VERSION ""

NS_ :

BS_:

BU_: ENGINE ABS AIRBAG BODY_CONTROL DIAG_TOOL

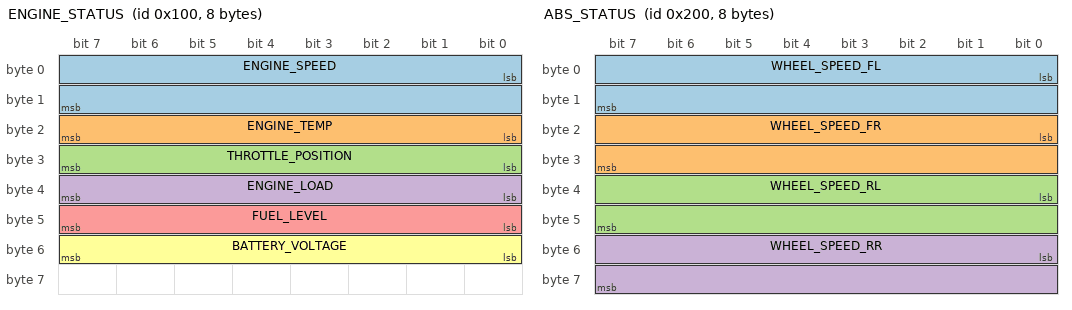
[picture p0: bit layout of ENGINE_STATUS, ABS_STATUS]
BO_ 256 ENGINE_STATUS: 8 ENGINE
 SG_ ENGINE_SPEED : 0|16@1+ (1,0) [0|16383] "rpm" BODY_CONTROL,DIAG_TOOL
 SG_ ENGINE_TEMP : 16|8@1+ (0.5,-40) [-40|127.5] "degC" BODY_CONTROL,DIAG_TOOL
 SG_ THROTTLE_POSITION : 24|8@1+ (0.4,0) [0|100] "%" BODY_CONTROL,DIAG_TOOL
 SG_ ENGINE_LOAD : 32|8@1+ (0.4,0) [0|100] "%" BODY_CONTROL,DIAG_TOOL
 SG_ FUEL_LEVEL : 40|8@1+ (0.4,0) [0|100] "%" BODY_CONTROL,DIAG_TOOL
 SG_ BATTERY_VOLTAGE : 48|8@1+ (0.1,0) [0|25.5] "V" BODY_CONTROL,DIAG_TOOL

BO_ 512 ABS_STATUS: 8 ABS
 SG_ WHEEL_SPEED_FL : 0|16@1+ (0.01,0) [0|300] "kph" BODY_CONTROL,DIAG_TOOL
 SG_ WHEEL_SPEED_FR : 16|16@1+ (0.01,0) [0|300] "kph" BODY_CONTROL,DIAG_TOOL
 SG_ WHEEL_SPEED_RL : 32|16@1+ (0.01,0) [0|300] "kph" BODY_CONTROL,DIAG_TOOL
 SG_ WHEEL_SPEED_RR : 48|16@1+ (0.01,0) [0|300] "kph" BODY_CONTROL,DIAG_TOOL

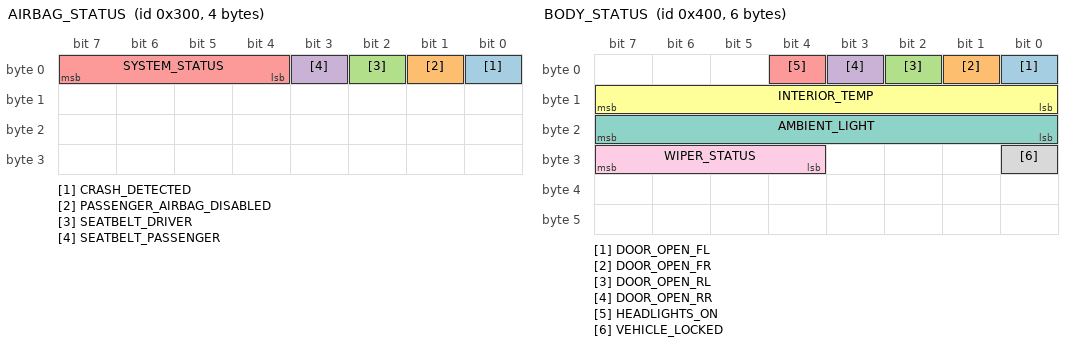
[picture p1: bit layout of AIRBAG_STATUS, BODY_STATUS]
BO_ 768 AIRBAG_STATUS: 4 AIRBAG
 SG_ CRASH_DETECTED : 0|1@1+ (1,0) [0|1] "" BODY_CONTROL,DIAG_TOOL
 SG_ PASSENGER_AIRBAG_DISABLED : 1|1@1+ (1,0) [0|1] "" BODY_CONTROL,DIAG_TOOL
 SG_ SEATBELT_DRIVER : 2|1@1+ (1,0) [0|1] "" BODY_CONTROL,DIAG_TOOL
 SG_ SEATBELT_PASSENGER : 3|1@1+ (1,0) [0|1] "" BODY_CONTROL,DIAG_TOOL
 SG_ SYSTEM_STATUS : 4|4@1+ (1,0) [0|15] "" BODY_CONTROL,DIAG_TOOL

BO_ 1024 BODY_STATUS: 6 BODY_CONTROL
 SG_ DOOR_OPEN_FL : 0|1@1+ (1,0) [0|1] "" DIAG_TOOL
 SG_ DOOR_OPEN_FR : 1|1@1+ (1,0) [0|1] "" DIAG_TOOL
 SG_ DOOR_OPEN_RL : 2|1@1+ (1,0) [0|1] "" DIAG_TOOL
 SG_ DOOR_OPEN_RR : 3|1@1+ (1,0) [0|1] "" DIAG_TOOL
 SG_ HEADLIGHTS_ON : 4|1@1+ (1,0) [0|1] "" DIAG_TOOL
 SG_ INTERIOR_TEMP : 8|8@1+ (0.5,-40) [-40|127.5] "degC" DIAG_TOOL
 SG_ AMBIENT_LIGHT : 16|8@1+ (1,0) [0|255] "lux" DIAG_TOOL
 SG_ VEHICLE_LOCKED : 24|1@1+ (1,0) [0|1] "" DIAG_TOOL
 SG_ WIPER_STATUS : 28|4@1+ (1,0) [0|15] "" DIAG_TOOL

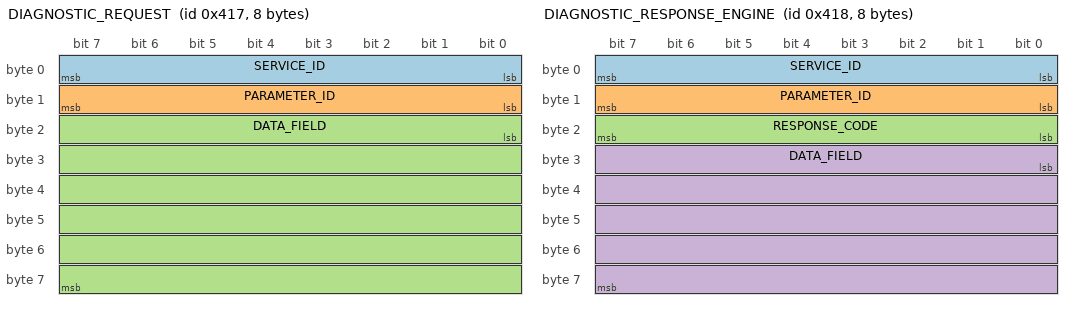
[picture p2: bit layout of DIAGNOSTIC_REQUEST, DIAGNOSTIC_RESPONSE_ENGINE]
BO_ 1047 DIAGNOSTIC_REQUEST: 8 DIAG_TOOL
 SG_ SERVICE_ID : 0|8@1+ (1,0) [0|255] "" ENGINE,ABS,AIRBAG,BODY_CONTROL
 SG_ PARAMETER_ID : 8|8@1+ (1,0) [0|255] "" ENGINE,ABS,AIRBAG,BODY_CONTROL
 SG_ DATA_FIELD : 16|48@1+ (1,0) [0|281474976710655] "" ENGINE,ABS,AIRBAG,BODY_CONTROL

BO_ 1048 DIAGNOSTIC_RESPONSE_ENGINE: 8 ENGINE
 SG_ SERVICE_ID : 0|8@1+ (1,0) [0|255] "" DIAG_TOOL
 SG_ PARAMETER_ID : 8|8@1+ (1,0) [0|255] "" DIAG_TOOL
 SG_ RESPONSE_CODE : 16|8@1+ (1,0) [0|255] "" DIAG_TOOL
 SG_ DATA_FIELD : 24|40@1+ (1,0) [0|1099511627775] "" DIAG_TOOL

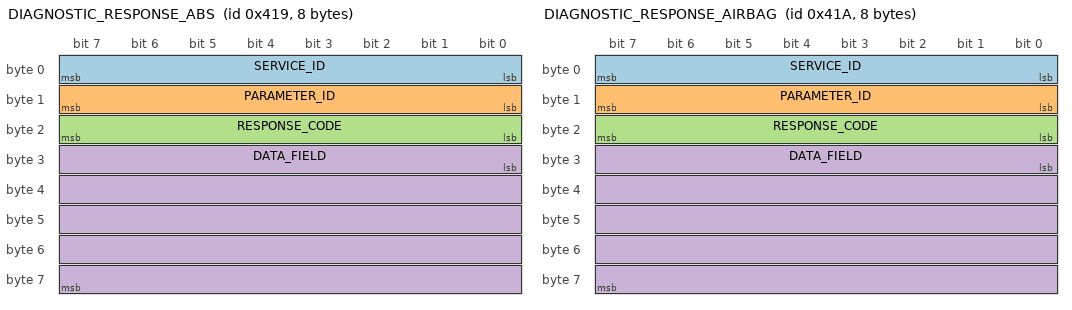
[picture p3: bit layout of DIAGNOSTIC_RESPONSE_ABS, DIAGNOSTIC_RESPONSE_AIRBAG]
BO_ 1049 DIAGNOSTIC_RESPONSE_ABS: 8 ABS
 SG_ SERVICE_ID : 0|8@1+ (1,0) [0|255] "" DIAG_TOOL
 SG_ PARAMETER_ID : 8|8@1+ (1,0) [0|255] "" DIAG_TOOL
 SG_ RESPONSE_CODE : 16|8@1+ (1,0) [0|255] "" DIAG_TOOL
 SG_ DATA_FIELD : 24|40@1+ (1,0) [0|1099511627775] "" DIAG_TOOL

BO_ 1050 DIAGNOSTIC_RESPONSE_AIRBAG: 8 AIRBAG
 SG_ SERVICE_ID : 0|8@1+ (1,0) [0|255] "" DIAG_TOOL
 SG_ PARAMETER_ID : 8|8@1+ (1,0) [0|255] "" DIAG_TOOL
 SG_ RESPONSE_CODE : 16|8@1+ (1,0) [0|255] "" DIAG_TOOL
 SG_ DATA_FIELD : 24|40@1+ (1,0) [0|1099511627775] "" DIAG_TOOL

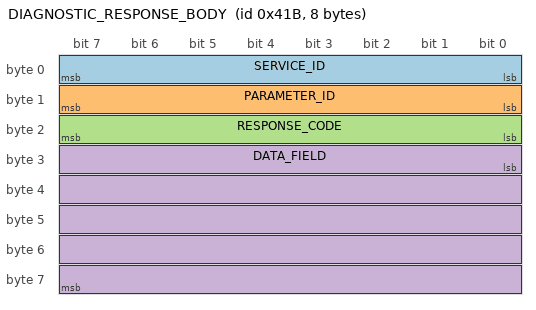
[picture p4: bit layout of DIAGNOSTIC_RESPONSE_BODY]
BO_ 1051 DIAGNOSTIC_RESPONSE_BODY: 8 BODY_CONTROL
 SG_ SERVICE_ID : 0|8@1+ (1,0) [0|255] "" DIAG_TOOL
 SG_ PARAMETER_ID : 8|8@1+ (1,0) [0|255] "" DIAG_TOOL
 SG_ RESPONSE_CODE : 16|8@1+ (1,0) [0|255] "" DIAG_TOOL
 SG_ DATA_FIELD : 24|40@1+ (1,0) [0|1099511627775] "" DIAG_TOOL

BA_DEF_ BO_ "FrameFormat" ENUM "StandardCAN","ExtendedCAN";
BA_ "FrameFormat" BO_ 1048 1;
BA_ "FrameFormat" BO_ 1049 1;
BA_ "FrameFormat" BO_ 1050 1;
BA_ "FrameFormat" BO_ 1051 1;
BA_ "FrameFormat" BO_ 1047 1;

CM_ SG_ 256 ENGINE_SPEED "Current engine RPM";
CM_ SG_ 256 ENGINE_TEMP "Engine coolant temperature";
CM_ SG_ 256 THROTTLE_POSITION "Current throttle pedal position";
CM_ SG_ 256 BATTERY_VOLTAGE "System (battery) voltage";
CM_ SG_ 1047 SERVICE_ID "Service identifier for diagnostic requests (e.g. 0x22 = Read Data)";
CM_ SG_ 1047 PARAMETER_ID "Parameter identifier for the requested data";
CM_ BO_ 1048 "Diagnostic response from Engine ECU";
CM_ BO_ 1049 "Diagnostic response from ABS ECU";
CM_ BO_ 1050 "Diagnostic response from Airbag ECU";
CM_ BO_ 1051 "Diagnostic response from Body Control ECU";

VAL_ 768 SYSTEM_STATUS 0 "OK" 1 "FAULT_PRESENT" 2 "CALIBRATION_REQUIRED" 3 "DISABLED" ;
VAL_ 1024 WIPER_STATUS 0 "OFF" 1 "INTERMITTENT_1" 2 "INTERMITTENT_2" 3 "INTERMITTENT_3" 4 "LOW_SPEED" 5 "HIGH_SPEED" ;
VAL_ 1047 SERVICE_ID 16 "START_DIAGNOSTIC_SESSION" 17 "RESET_ECU" 34 "READ_DATA_BY_ID" 47 "ROUTINE_CONTROL" 49 "READ_MEMORY" 50 "WRITE_MEMORY" ;
VAL_ 1048 RESPONSE_CODE 0 "OK" 1 "GENERAL_REJECT" 17 "SERVICE_NOT_SUPPORTED" 33 "INVALID_FORMAT" 34 "CONDITION_NOT_CORRECT" ;
